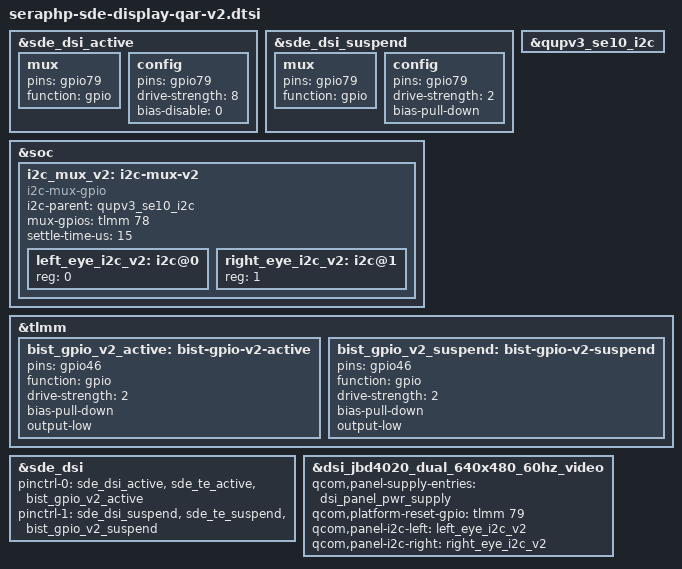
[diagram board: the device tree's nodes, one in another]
// SPDX-License-Identifier: BSD-3-Clause
/*
 * Copyright (c) Qualcomm Technologies, Inc. and/or its subsidiaries.
 */

#include "seraphp-sde-display-qar.dtsi"

&sde_dsi_active {
	mux {
		pins = "gpio79";
		function = "gpio";
	};

	config {
		pins = "gpio79";
		drive-strength = <8>;   /* 8 mA */
		bias-disable = <0>;   /* no pull */
	};
};

&sde_dsi_suspend {
	mux {
		pins = "gpio79";
		function = "gpio";
	};

	config {
		pins = "gpio79";
		drive-strength = <2>;   /* 2 mA */
		bias-pull-down;         /* PULL DOWN */
	};
};

&qupv3_se10_i2c {
	status = "okay";
};

&soc {
	i2c_mux_v2: i2c-mux-v2 {
		compatible = "i2c-mux-gpio";
		i2c-parent = <&qupv3_se10_i2c>;
		mux-gpios = <&tlmm 78 GPIO_ACTIVE_HIGH>;
		settle-time-us = <15>;

		#address-cells = <1>;
		#size-cells = <0>;

		left_eye_i2c_v2: i2c@0 {
			reg = <0>;
			#address-cells = <1>;
			#size-cells = <0>;
		};

		right_eye_i2c_v2: i2c@1 {
			reg = <1>;
			#address-cells = <1>;
			#size-cells = <0>;
		};
	};
};

&tlmm {
	bist_gpio_v2_active: bist-gpio-v2-active {
		pins = "gpio46";
		function = "gpio";
		drive-strength = <2>;
		bias-pull-down;
		output-low;
	};

	bist_gpio_v2_suspend: bist-gpio-v2-suspend {
		pins = "gpio46";
		function = "gpio";
		drive-strength = <2>;
		bias-pull-down;
		output-low;
	};
};

&sde_dsi {
	pinctrl-0 = <&sde_dsi_active &sde_te_active &bist_gpio_v2_active>;
	pinctrl-1 = <&sde_dsi_suspend &sde_te_suspend &bist_gpio_v2_suspend>;
};

&dsi_jbd4020_dual_640x480_60hz_video {
	qcom,panel-supply-entries = <&dsi_panel_pwr_supply>;
	qcom,platform-reset-gpio = <&tlmm 79 0>;
	qcom,panel-i2c-left  = <&left_eye_i2c_v2>;
	qcom,panel-i2c-right  = <&right_eye_i2c_v2>;
};

